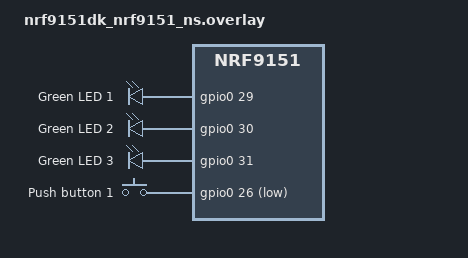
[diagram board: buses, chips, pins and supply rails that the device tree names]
/*
 * Copyright (c) 2024 Nordic Semiconductor ASA
 *
 * SPDX-License-Identifier: LicenseRef-Nordic-5-Clause
 */

/ {
    leds {
		compatible = "gpio-leds";
		led0: led_0 {
			gpios = <&gpio0 29 GPIO_ACTIVE_HIGH>;
			label = "Green LED 1";
		};
		led1: led_1 {
			gpios = <&gpio0 30 GPIO_ACTIVE_HIGH>;
			label = "Green LED 2";
		};
		led2: led_2 {
			gpios = <&gpio0 31 GPIO_ACTIVE_HIGH>;
			label = "Green LED 3";
		};
	};

	buttons {
		compatible = "gpio-keys";
		button0: button_0 {
			gpios = <&gpio0 26 (GPIO_PULL_UP | GPIO_ACTIVE_LOW)>;
			label = "Push button 1";
			zephyr,code = <INPUT_KEY_0>;
		};
	};
};

&pinctrl {
	uart0_default: uart0_default {
		group1 {
			psels = <NRF_PSEL(UART_TX, 0, 0)>;
		};
		group2 {
			psels = <NRF_PSEL(UART_RX, 0, 1)>;
			bias-pull-up;
		};
	};

	uart0_sleep: uart0_sleep {
		group1 {
			psels = <NRF_PSEL(UART_TX, 0, 0)>,
				<NRF_PSEL(UART_RX, 0, 1)>;
			low-power-enable;
		};
	};
};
